AUTOSAR XML (schema 4-2-2)
package /STELLANTIS/EPT/ASWCs
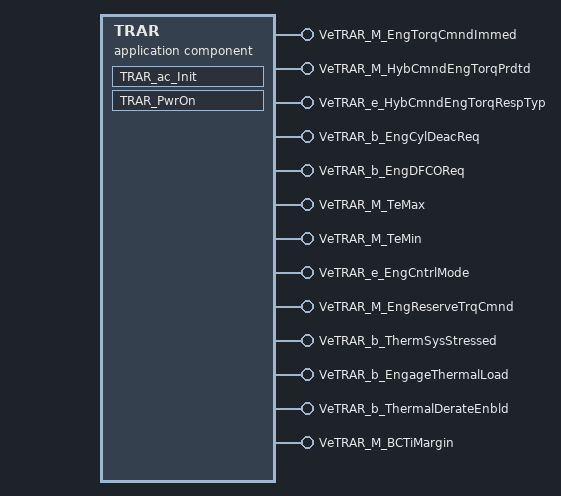
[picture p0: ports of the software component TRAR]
  application sw component type TRAR
    13 x provide port:
      VeTRAR_M_EngTorqCmndImmed: variation-point={short-label=vpVeTRAR_M_EngTorqCmndImmed, sw-syscond=1}, nonqueued-sender-com-spec{data-element=Value, init-value=0}, provided-interface=VeTRAR_M_EngTorqCmndImmed
      VeTRAR_M_HybCmndEngTorqPrdtd: variation-point={short-label=vpVeTRAR_M_HybCmndEngTorqPrdtd, sw-syscond=1}, nonqueued-sender-com-spec{data-element=Value, init-value=0}, provided-interface=VeTRAR_M_HybCmndEngTorqPrdtd
      VeTRAR_e_HybCmndEngTorqRespTyp: variation-point={short-label=vpVeTRAR_e_HybCmndEngTorqRespTyp, sw-syscond=1}, nonqueued-sender-com-spec{data-element=Value, init-value=CeTRAR_e_Inactive}, provided-interface=VeTRAR_e_HybCmndEngTorqRespTyp
      VeTRAR_b_EngCylDeacReq: variation-point={short-label=vpVeTRAR_b_EngCylDeacReq, sw-syscond=1}, nonqueued-sender-com-spec{data-element=Value, init-value=0}, provided-interface=VeTRAR_b_EngCylDeacReq
      VeTRAR_b_EngDFCOReq: variation-point={short-label=vpVeTRAR_b_EngDFCOReq, sw-syscond=1}, nonqueued-sender-com-spec{data-element=Value, init-value=0}, provided-interface=VeTRAR_b_EngDFCOReq
      VeTRAR_M_TeMax: variation-point={short-label=vpVeTRAR_M_TeMax, sw-syscond=1}, nonqueued-sender-com-spec{data-element=Value, init-value=0}, provided-interface=VeTRAR_M_TeMax
      VeTRAR_M_TeMin: variation-point={short-label=vpVeTRAR_M_TeMin, sw-syscond=1}, nonqueued-sender-com-spec{data-element=Value, init-value=0}, provided-interface=VeTRAR_M_TeMin
      VeTRAR_e_EngCntrlMode: variation-point={short-label=vpVeTRAR_e_EngCntrlMode, sw-syscond=1}, nonqueued-sender-com-spec{data-element=Value, init-value=CeTRAR_e_TorqueMode}, provided-interface=VeTRAR_e_EngCntrlMode
      VeTRAR_M_EngReserveTrqCmnd: variation-point={short-label=vpVeTRAR_M_EngReserveTrqCmnd, sw-syscond=1}, nonqueued-sender-com-spec{data-element=Value, init-value=0}, provided-interface=VeTRAR_M_EngReserveTrqCmnd
      VeTRAR_b_ThermSysStressed: variation-point={short-label=vpVeTRAR_b_ThermSysStressed, sw-syscond=1}, nonqueued-sender-com-spec{data-element=Value, init-value=0}, provided-interface=VeTRAR_b_ThermSysStressed
      VeTRAR_b_EngageThermalLoad: variation-point={short-label=vpVeTRAR_b_EngageThermalLoad, sw-syscond=1}, nonqueued-sender-com-spec{data-element=Value, init-value=0}, provided-interface=VeTRAR_b_EngageThermalLoad
      VeTRAR_b_ThermalDerateEnbld: variation-point={short-label=vpVeTRAR_b_ThermalDerateEnbld, sw-syscond=1}, nonqueued-sender-com-spec{data-element=Value, init-value=0}, provided-interface=VeTRAR_b_ThermalDerateEnbld
      VeTRAR_M_BCTiMargin: variation-point={short-label=vpVeTRAR_M_BCTiMargin, sw-syscond=1}, nonqueued-sender-com-spec{data-element=Value, init-value=0}, provided-interface=VeTRAR_M_BCTiMargin
    behavior IB_TRAR: data-type-mapping=msADTtoIDTMapping, handle-termination-and-restart=NO-SUPPORT, included-data-type-set=data-type=[TeTRAR_e_EngArbState, TeTRAR_e_EngState]
      init event Event_TRAR_ac_Init: start-on-event=TRAR_ac_Init
      init event Event_PwrOn: start-on-event=TRAR_PwrOn
      runnable TRAR_ac_Init
        data-send-points:
          access OUT_VeTRAR_e_HybCmndEngTorqRespTyp_Value: accessed-variable=VeTRAR_e_HybCmndEngTorqRespTyp.Value, variation-point={short-label=vpOUT_VeTRAR_e_HybCmndEngTorqRespTyp_Value, sw-syscond=1}
          access OUT_VeTRAR_e_EngCntrlMode_Value: accessed-variable=VeTRAR_e_EngCntrlMode.Value, variation-point={short-label=vpOUT_VeTRAR_e_EngCntrlMode_Value, sw-syscond=1}
      runnable TRAR_PwrOn: variation-point={short-label=vpTRAR_PwrOn, sw-syscond=1}
        data-send-points:
          13 x access:
            OUT_VeTRAR_M_EngTorqCmndImmed_Value: accessed-variable=VeTRAR_M_EngTorqCmndImmed.Value, variation-point={short-label=vpOUT_VeTRAR_M_EngTorqCmndImmed_Value, sw-syscond=1}
            OUT_VeTRAR_M_HybCmndEngTorqPrdtd_Value: accessed-variable=VeTRAR_M_HybCmndEngTorqPrdtd.Value, variation-point={short-label=vpOUT_VeTRAR_M_HybCmndEngTorqPrdtd_Value, sw-syscond=1}
            OUT_VeTRAR_b_EngCylDeacReq_Value: accessed-variable=VeTRAR_b_EngCylDeacReq.Value, variation-point={short-label=vpOUT_VeTRAR_b_EngCylDeacReq_Value, sw-syscond=1}
            OUT_VeTRAR_M_TeMax_Value: accessed-variable=VeTRAR_M_TeMax.Value, variation-point={short-label=vpOUT_VeTRAR_M_TeMax_Value, sw-syscond=1}
            OUT_VeTRAR_M_TeMin_Value: accessed-variable=VeTRAR_M_TeMin.Value, variation-point={short-label=vpOUT_VeTRAR_M_TeMin_Value, sw-syscond=1}
            OUT_VeTRAR_e_EngCntrlMode_Value: accessed-variable=VeTRAR_e_EngCntrlMode.Value, variation-point={short-label=vpOUT_VeTRAR_e_EngCntrlMode_Value, sw-syscond=1}
            OUT_VeTRAR_b_ThermSysStressed_Value: accessed-variable=VeTRAR_b_ThermSysStressed.Value, variation-point={short-label=vpOUT_VeTRAR_b_ThermSysStressed_Value, sw-syscond=1}
            OUT_VeTRAR_b_EngageThermalLoad_Value: accessed-variable=VeTRAR_b_EngageThermalLoad.Value, variation-point={short-label=vpOUT_VeTRAR_b_EngageThermalLoad_Value, sw-syscond=1}
            OUT_VeTRAR_b_ThermalDerateEnbld_Value: accessed-variable=VeTRAR_b_ThermalDerateEnbld.Value, variation-point={short-label=vpOUT_VeTRAR_b_ThermalDerateEnbld_Value, sw-syscond=1}
            OUT_VeTRAR_M_EngReserveTrqCmnd_Value: accessed-variable=VeTRAR_M_EngReserveTrqCmnd.Value, variation-point={short-label=vpOUT_VeTRAR_M_EngReserveTrqCmnd_Value, sw-syscond=1}
            OUT_VeTRAR_b_EngDFCOReq_Value: accessed-variable=VeTRAR_b_EngDFCOReq.Value, variation-point={short-label=vpOUT_VeTRAR_b_EngDFCOReq_Value, sw-syscond=1}
            OUT_VeTRAR_e_HybCmndEngTorqRespTyp_Value: accessed-variable=VeTRAR_e_HybCmndEngTorqRespTyp.Value, variation-point={short-label=vpOUT_VeTRAR_e_HybCmndEngTorqRespTyp_Value, sw-syscond=1}
            OUT_VeTRAR_M_BCTiMargin_Value: accessed-variable=VeTRAR_M_BCTiMargin.Value, variation-point={short-label=vpOUT_VeTRAR_M_BCTiMargin_Value, sw-syscond=1}
      4 x variation point proxy, all with category=CONDITION:
        Variant_TRAR_1: condition-access=1
        Variant_TRAR_2: condition-access=0
        Variant_TRAR_BoostedConverter_Enable: condition-access=0
        Variant_TRAR_DistrbtdSEMCntrlStrat_Enable: condition-access=0
